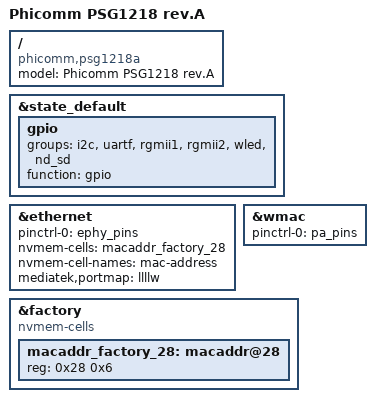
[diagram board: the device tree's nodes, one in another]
#include "mt7620a_phicomm_psg1218.dtsi"

/ {
	compatible = "phicomm,psg1218a", "phicomm,psg1218", "ralink,mt7620a-soc";
	model = "Phicomm PSG1218 rev.A";
};

&state_default {
	gpio {
		groups = "i2c", "uartf", "rgmii1", "rgmii2", "wled", "nd_sd";
		function = "gpio";
	};
};

&ethernet {
	pinctrl-names = "default";
	pinctrl-0 = <&ephy_pins>;

	nvmem-cells = <&macaddr_factory_28>;
	nvmem-cell-names = "mac-address";

	mediatek,portmap = "llllw";
};

&wmac {
	pinctrl-names = "default";
	pinctrl-0 = <&pa_pins>;
};

&factory {
	compatible = "nvmem-cells";
	#address-cells = <1>;
	#size-cells = <1>;

	macaddr_factory_28: macaddr@28 {
		reg = <0x28 0x6>;
	};
};
